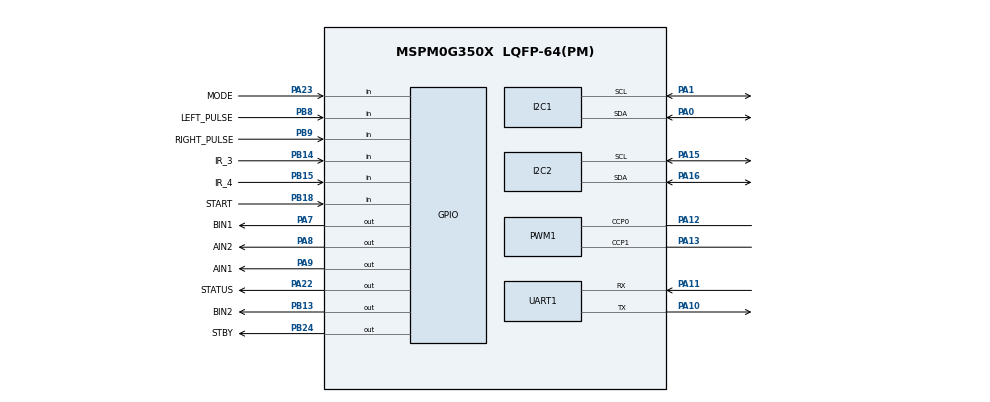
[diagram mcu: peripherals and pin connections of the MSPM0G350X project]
/**
 * @cliArgs --device "MSPM0G350X" --part "Default" --package "LQFP-64(PM)" --product "mspm0_sdk@2.10.00.04"
 * @versions {"tool":"1.26.2+4477"}
 */

/**
 * Import the modules used in this configuration.
 */
const GPIO   = scripting.addModule("/ti/driverlib/GPIO", {}, false);
const GPIO1  = GPIO.addInstance();
const GPIO2  = GPIO.addInstance();
const GPIO3  = GPIO.addInstance();
const GPIO4  = GPIO.addInstance();
const GPIO5  = GPIO.addInstance();
const I2C    = scripting.addModule("/ti/driverlib/I2C", {}, false);
const I2C1   = I2C.addInstance();
const I2C2   = I2C.addInstance();
const PWM    = scripting.addModule("/ti/driverlib/PWM", {}, false);
const PWM1   = PWM.addInstance();
const SYSCTL = scripting.addModule("/ti/driverlib/SYSCTL");
const TIMER  = scripting.addModule("/ti/driverlib/TIMER", {}, false);
const TIMER1 = TIMER.addInstance();
const UART   = scripting.addModule("/ti/driverlib/UART", {}, false);
const UART1  = UART.addInstance();

/**
 * Write custom configuration values to the imported modules.
 */
const divider9       = system.clockTree["UDIV"];
divider9.divideValue = 2;

const multiplier2         = system.clockTree["PLL_QDIV"];
multiplier2.multiplyValue = 5;

const mux4       = system.clockTree["EXHFMUX"];
mux4.inputSelect = "EXHFMUX_XTAL";

const mux8       = system.clockTree["HSCLKMUX"];
mux8.inputSelect = "HSCLKMUX_SYSPLL0";

const pinFunction4     = system.clockTree["HFXT"];
pinFunction4.inputFreq = 40;
pinFunction4.enable    = true;

GPIO1.$name                                       = "Infrared";
GPIO1.associatedPins.create(4);
GPIO1.associatedPins[0].$name                     = "IR_1";
GPIO1.associatedPins[0].direction                 = "INPUT";
GPIO1.associatedPins[0].internalResistor          = "PULL_UP";
GPIO1.associatedPins[0].pin.$assignAllowConflicts = "PA14";
GPIO1.associatedPins[1].$name                     = "IR_2";
GPIO1.associatedPins[1].direction                 = "INPUT";
GPIO1.associatedPins[1].internalResistor          = "PULL_UP";
GPIO1.associatedPins[1].pin.$assignAllowConflicts = "PB16";
GPIO1.associatedPins[2].$name                     = "IR_3";
GPIO1.associatedPins[2].direction                 = "INPUT";
GPIO1.associatedPins[2].internalResistor          = "PULL_UP";
GPIO1.associatedPins[2].pin.$assign               = "PB14";
GPIO1.associatedPins[3].$name                     = "IR_4";
GPIO1.associatedPins[3].direction                 = "INPUT";
GPIO1.associatedPins[3].internalResistor          = "PULL_UP";
GPIO1.associatedPins[3].pin.$assign               = "PB15";

const Board = scripting.addModule("/ti/driverlib/Board", {}, false);

GPIO2.$name                         = "DC_MOTOR";
GPIO2.associatedPins.create(5);
GPIO2.associatedPins[0].$name       = "AIN1";
GPIO2.associatedPins[0].pin.$assign = "PA9";
GPIO2.associatedPins[1].$name       = "AIN2";
GPIO2.associatedPins[1].pin.$assign = "PA8";
GPIO2.associatedPins[2].$name       = "STBY";
GPIO2.associatedPins[2].pin.$assign = "PB24";
GPIO2.associatedPins[3].$name       = "BIN1";
GPIO2.associatedPins[3].pin.$assign = "PA7";
GPIO2.associatedPins[4].$name       = "BIN2";
GPIO2.associatedPins[4].pin.$assign = "PB13";

GPIO3.$name                              = "ENCODER";
GPIO3.associatedPins.create(2);
GPIO3.associatedPins[0].$name            = "LEFT_PULSE";
GPIO3.associatedPins[0].direction        = "INPUT";
GPIO3.associatedPins[0].internalResistor = "PULL_UP";
GPIO3.associatedPins[0].interruptEn      = true;
GPIO3.associatedPins[0].polarity         = "RISE";
GPIO3.associatedPins[0].pin.$assign      = "PB8";
GPIO3.associatedPins[1].$name            = "RIGHT_PULSE";
GPIO3.associatedPins[1].direction        = "INPUT";
GPIO3.associatedPins[1].internalResistor = "PULL_UP";
GPIO3.associatedPins[1].interruptEn      = true;
GPIO3.associatedPins[1].polarity         = "RISE";
GPIO3.associatedPins[1].pin.$assign      = "PB9";

GPIO4.$name                              = "BUTTONS";
GPIO4.associatedPins.create(2);
GPIO4.associatedPins[0].$name            = "MODE";
GPIO4.associatedPins[0].direction        = "INPUT";
GPIO4.associatedPins[0].internalResistor = "PULL_UP";
GPIO4.associatedPins[0].pin.$assign      = "PA23";
GPIO4.associatedPins[1].$name            = "START";
GPIO4.associatedPins[1].direction        = "INPUT";
GPIO4.associatedPins[1].internalResistor = "PULL_UP";
GPIO4.associatedPins[1].pin.$assign      = "PB18";

GPIO5.$name                         = "LED";
GPIO5.port                          = "PORTA";
GPIO5.associatedPins[0].$name       = "STATUS";
GPIO5.associatedPins[0].pin.$assign = "PA22";

I2C1.$name                             = "OLED";
I2C1.basicEnableController             = true;
I2C1.advDigitalGlitchFilter            = "CLOCKS_1";
I2C1.advControllerRXFIFOTRIG           = "BYTES_8";
I2C1.advControllerTXFIFOTRIG           = "BYTES_7";
I2C1.peripheral.$assign                = "I2C0";
I2C1.peripheral.sdaPin.$assign         = "PA0";
I2C1.peripheral.sclPin.$assign         = "PA1";
I2C1.sdaPinConfig.hideOutputInversion  = scripting.forceWrite(false);
I2C1.sdaPinConfig.onlyInternalResistor = scripting.forceWrite(false);
I2C1.sdaPinConfig.passedPeripheralType = scripting.forceWrite("Digital");
I2C1.sdaPinConfig.$name                = "OLED_SDA_PIN";
I2C1.sdaPinConfig.enableConfig         = true;
I2C1.sclPinConfig.hideOutputInversion  = scripting.forceWrite(false);
I2C1.sclPinConfig.onlyInternalResistor = scripting.forceWrite(false);
I2C1.sclPinConfig.passedPeripheralType = scripting.forceWrite("Digital");
I2C1.sclPinConfig.$name                = "OLED_SCL_PIN";
I2C1.sclPinConfig.enableConfig         = true;

I2C2.$name                             = "MS6DSV";
I2C2.basicEnableController             = true;
I2C2.advDigitalGlitchFilter            = "CLOCKS_1";
I2C2.advControllerRXFIFOTRIG           = "BYTES_8";
I2C2.advControllerTXFIFOTRIG           = "BYTES_7";
I2C2.peripheral.$assign                = "I2C1";
I2C2.peripheral.sdaPin.$assign         = "PA16";
I2C2.peripheral.sclPin.$assign         = "PA15";
I2C2.sdaPinConfig.hideOutputInversion  = scripting.forceWrite(false);
I2C2.sdaPinConfig.onlyInternalResistor = scripting.forceWrite(false);
I2C2.sdaPinConfig.passedPeripheralType = scripting.forceWrite("Digital");
I2C2.sdaPinConfig.$name                = "MS6DSV_SDA_PIN";
I2C2.sdaPinConfig.enableConfig         = true;
I2C2.sdaPinConfig.internalResistor     = "PULL_UP";
I2C2.sclPinConfig.hideOutputInversion  = scripting.forceWrite(false);
I2C2.sclPinConfig.onlyInternalResistor = scripting.forceWrite(false);
I2C2.sclPinConfig.passedPeripheralType = scripting.forceWrite("Digital");
I2C2.sclPinConfig.$name                = "MS6DSV_SCL_PIN";
I2C2.sclPinConfig.enableConfig         = true;
I2C2.sclPinConfig.internalResistor     = "PULL_UP";

PWM1.$name                              = "PWMAB";
PWM1.timerStartTimer                    = true;
PWM1.timerCount                         = 4000;
PWM1.pwmMode                            = "EDGE_ALIGN_UP";
PWM1.peripheral.$assign                 = "TIMG0";
PWM1.peripheral.ccp0Pin.$assign         = "PA12";
PWM1.peripheral.ccp1Pin.$assign         = "PA13";
PWM1.PWM_CHANNEL_0.$name                = "PWMAB_CHANNEL_A";
PWM1.PWM_CHANNEL_1.$name                = "PWMAB_CHANNEL_B";
PWM1.ccp0PinConfig.direction            = scripting.forceWrite("OUTPUT");
PWM1.ccp0PinConfig.hideOutputInversion  = scripting.forceWrite(false);
PWM1.ccp0PinConfig.onlyInternalResistor = scripting.forceWrite(false);
PWM1.ccp0PinConfig.passedPeripheralType = scripting.forceWrite("Digital");
PWM1.ccp0PinConfig.$name                = "PWMAB_A_PIN";
PWM1.ccp1PinConfig.direction            = scripting.forceWrite("OUTPUT");
PWM1.ccp1PinConfig.hideOutputInversion  = scripting.forceWrite(false);
PWM1.ccp1PinConfig.onlyInternalResistor = scripting.forceWrite(false);
PWM1.ccp1PinConfig.passedPeripheralType = scripting.forceWrite("Digital");
PWM1.ccp1PinConfig.$name                = "PWMAB_B_PIN";

SYSCTL.forceDefaultClkConfig = true;
SYSCTL.clockTreeEn           = true;

TIMER1.$name              = "MOTOR_PID";
TIMER1.timerMode          = "PERIODIC_UP";
TIMER1.timerPeriod        = "50ms";
TIMER1.timerClkPrescale   = 100;
TIMER1.interrupts         = ["LOAD"];
TIMER1.peripheral.$assign = "TIMA0";

UART1.$name                    = "TELEMETRY_UART";
UART1.targetBaudRate           = 115200;
UART1.peripheral.$assign       = "UART0";
UART1.peripheral.txPin.$assign = "PA10";
UART1.peripheral.rxPin.$assign = "PA11";

/**
 * Pinmux solution for unlocked pins/peripherals. This ensures that minor changes to the automatic solver in a future
 * version of the tool will not impact the pinmux you originally saw.  These lines can be completely deleted in order to
 * re-solve from scratch.
 */
pinFunction4.peripheral.$suggestSolution           = "SYSCTL";
pinFunction4.peripheral.hfxInPin.$suggestSolution  = "PA5";
pinFunction4.peripheral.hfxOutPin.$suggestSolution = "PA6";
Board.peripheral.$suggestSolution                  = "DEBUGSS";
Board.peripheral.swclkPin.$suggestSolution         = "PA20";
Board.peripheral.swdioPin.$suggestSolution         = "PA19";
